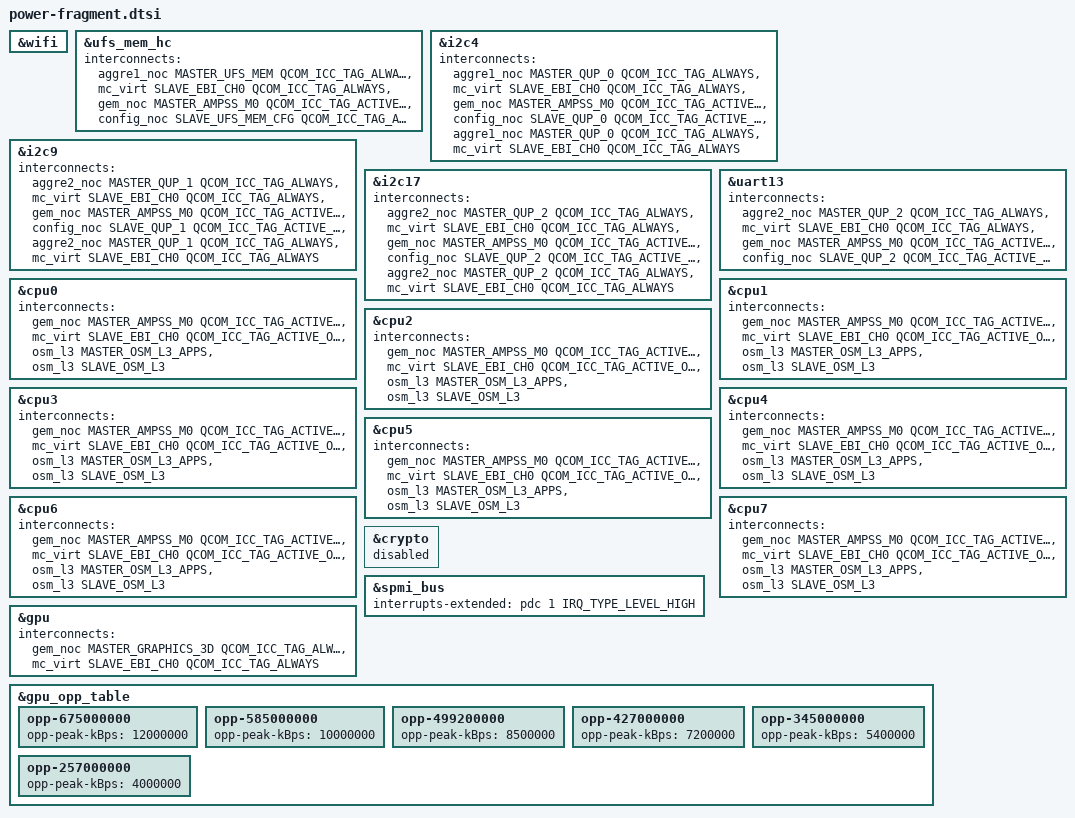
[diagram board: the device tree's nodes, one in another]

/* Idle power test (2026-11-10): ath10k holds both clocks for as long as
 * Wi-Fi is up. rf_clk2 keeps CXO on (blocks aosd); qdss is a debug vote.
 * Both are optional in ath10k_snoc. Test whether WCN3990 still works with
 * the crystal requested by its own pin, as on Android. */
&wifi {
	/delete-property/ clocks;
	/delete-property/ clock-names;
};

/* Interconnect votes missing from sm8150.dtsi (2026-11-10). qnoc-sm8150 had
 * no sync_state, so every NoC/DDR stayed at boot bandwidth (INT_MAX) forever
 * and the SoC could never sleep. With sync_state added, masters without
 * votes lose their bus: UFS (aggre1 path) and the QUP core clock (bcm_qup0,
 * which only QUP master paths vote) stall and the phone crashes. Give them
 * votes as sm8250 does. The device->DDR paths must be tagged "always":
 * tagged active-only they vanish from the bus the moment the last CPU
 * idles, even with a transfer in flight, and UFS then stalls for good
 * (seen 2026-11-12: every block tag stuck, phone half dead). The drivers
 * drop these votes themselves when the device is idle (UFS clock gating,
 * GENI runtime suspend). Only the cpu->register paths are active-only.
 * The QUP core clock
 * BCM sits on the QUP master nodes (no qup_virt on sm8150), so a QUP->DDR
 * path doubles as "qup-core". */
#include <dt-bindings/interconnect/qcom,icc.h>

&ufs_mem_hc {
	interconnects = <&aggre1_noc MASTER_UFS_MEM QCOM_ICC_TAG_ALWAYS &mc_virt SLAVE_EBI_CH0 QCOM_ICC_TAG_ALWAYS>,
			<&gem_noc MASTER_AMPSS_M0 QCOM_ICC_TAG_ACTIVE_ONLY &config_noc SLAVE_UFS_MEM_CFG QCOM_ICC_TAG_ACTIVE_ONLY>;
	interconnect-names = "ufs-ddr", "cpu-ufs";
};

&i2c4 {
	interconnects = <&aggre1_noc MASTER_QUP_0 QCOM_ICC_TAG_ALWAYS &mc_virt SLAVE_EBI_CH0 QCOM_ICC_TAG_ALWAYS>,
			<&gem_noc MASTER_AMPSS_M0 QCOM_ICC_TAG_ACTIVE_ONLY &config_noc SLAVE_QUP_0 QCOM_ICC_TAG_ACTIVE_ONLY>,
			<&aggre1_noc MASTER_QUP_0 QCOM_ICC_TAG_ALWAYS &mc_virt SLAVE_EBI_CH0 QCOM_ICC_TAG_ALWAYS>;
	interconnect-names = "qup-core", "qup-config", "qup-memory";
};

&i2c9 {
	interconnects = <&aggre2_noc MASTER_QUP_1 QCOM_ICC_TAG_ALWAYS &mc_virt SLAVE_EBI_CH0 QCOM_ICC_TAG_ALWAYS>,
			<&gem_noc MASTER_AMPSS_M0 QCOM_ICC_TAG_ACTIVE_ONLY &config_noc SLAVE_QUP_1 QCOM_ICC_TAG_ACTIVE_ONLY>,
			<&aggre2_noc MASTER_QUP_1 QCOM_ICC_TAG_ALWAYS &mc_virt SLAVE_EBI_CH0 QCOM_ICC_TAG_ALWAYS>;
	interconnect-names = "qup-core", "qup-config", "qup-memory";
};

&i2c17 {
	interconnects = <&aggre2_noc MASTER_QUP_2 QCOM_ICC_TAG_ALWAYS &mc_virt SLAVE_EBI_CH0 QCOM_ICC_TAG_ALWAYS>,
			<&gem_noc MASTER_AMPSS_M0 QCOM_ICC_TAG_ACTIVE_ONLY &config_noc SLAVE_QUP_2 QCOM_ICC_TAG_ACTIVE_ONLY>,
			<&aggre2_noc MASTER_QUP_2 QCOM_ICC_TAG_ALWAYS &mc_virt SLAVE_EBI_CH0 QCOM_ICC_TAG_ALWAYS>;
	interconnect-names = "qup-core", "qup-config", "qup-memory";
};

&uart13 {
	interconnects = <&aggre2_noc MASTER_QUP_2 QCOM_ICC_TAG_ALWAYS &mc_virt SLAVE_EBI_CH0 QCOM_ICC_TAG_ALWAYS>,
			<&gem_noc MASTER_AMPSS_M0 QCOM_ICC_TAG_ACTIVE_ONLY &config_noc SLAVE_QUP_2 QCOM_ICC_TAG_ACTIVE_ONLY>;
	interconnect-names = "qup-core", "qup-config";
};

/* cpu DDR vote (2026-11-12). Tag 0 means "always": the
 * cpufreq DDR bandwidth vote stayed in the RPMh sleep set, so DDR and the NoCs were never released
 * while every CPU was power-collapsed (aosd/cxsd/ddr stuck at 0). Vendor
 * kernels vote these in the active set only. */
&cpu0 {
	interconnects = <&gem_noc MASTER_AMPSS_M0 QCOM_ICC_TAG_ACTIVE_ONLY &mc_virt SLAVE_EBI_CH0 QCOM_ICC_TAG_ACTIVE_ONLY>,
			<&osm_l3 MASTER_OSM_L3_APPS &osm_l3 SLAVE_OSM_L3>;
};

&cpu1 {
	interconnects = <&gem_noc MASTER_AMPSS_M0 QCOM_ICC_TAG_ACTIVE_ONLY &mc_virt SLAVE_EBI_CH0 QCOM_ICC_TAG_ACTIVE_ONLY>,
			<&osm_l3 MASTER_OSM_L3_APPS &osm_l3 SLAVE_OSM_L3>;
};

&cpu2 {
	interconnects = <&gem_noc MASTER_AMPSS_M0 QCOM_ICC_TAG_ACTIVE_ONLY &mc_virt SLAVE_EBI_CH0 QCOM_ICC_TAG_ACTIVE_ONLY>,
			<&osm_l3 MASTER_OSM_L3_APPS &osm_l3 SLAVE_OSM_L3>;
};

&cpu3 {
	interconnects = <&gem_noc MASTER_AMPSS_M0 QCOM_ICC_TAG_ACTIVE_ONLY &mc_virt SLAVE_EBI_CH0 QCOM_ICC_TAG_ACTIVE_ONLY>,
			<&osm_l3 MASTER_OSM_L3_APPS &osm_l3 SLAVE_OSM_L3>;
};

&cpu4 {
	interconnects = <&gem_noc MASTER_AMPSS_M0 QCOM_ICC_TAG_ACTIVE_ONLY &mc_virt SLAVE_EBI_CH0 QCOM_ICC_TAG_ACTIVE_ONLY>,
			<&osm_l3 MASTER_OSM_L3_APPS &osm_l3 SLAVE_OSM_L3>;
};

&cpu5 {
	interconnects = <&gem_noc MASTER_AMPSS_M0 QCOM_ICC_TAG_ACTIVE_ONLY &mc_virt SLAVE_EBI_CH0 QCOM_ICC_TAG_ACTIVE_ONLY>,
			<&osm_l3 MASTER_OSM_L3_APPS &osm_l3 SLAVE_OSM_L3>;
};

&cpu6 {
	interconnects = <&gem_noc MASTER_AMPSS_M0 QCOM_ICC_TAG_ACTIVE_ONLY &mc_virt SLAVE_EBI_CH0 QCOM_ICC_TAG_ACTIVE_ONLY>,
			<&osm_l3 MASTER_OSM_L3_APPS &osm_l3 SLAVE_OSM_L3>;
};

&cpu7 {
	interconnects = <&gem_noc MASTER_AMPSS_M0 QCOM_ICC_TAG_ACTIVE_ONLY &mc_virt SLAVE_EBI_CH0 QCOM_ICC_TAG_ACTIVE_ONLY>,
			<&osm_l3 MASTER_OSM_L3_APPS &osm_l3 SLAVE_OSM_L3>;
};

/* The crypto engine holds a fixed DDR vote for as long as its driver is
 * bound and nothing uses it (ARMv8 CE is faster). Off. */
&crypto {
	status = "disabled";
};

/* PMIC wake through the PDC (2026-11-14). sm8150.dtsi wires the SPMI arbiter
 * interrupt straight to the GIC (SPI 481). In XO shutdown / AOSS sleep the GIC
 * is off and only PDC-routed interrupts wake the SoC, so the RTC alarm, the
 * charger and USB plug events could never wake it: the first real deep sleep
 * looked like a hang (no watchdog, no answer until a forced reset). sm8250
 * routes it as PDC pin 1, which maps to SPI 481 (qcom,pdc-ranges <0 480 94>). */
&spmi_bus {
	/delete-property/ interrupts;
	interrupts-extended = <&pdc 1 IRQ_TYPE_LEVEL_HIGH>;
};

/* GPU DDR bandwidth (2026-11-14). The A640 GMU table in a6xx_hfi.c is a
 * single "off" level (no bus scaling), and sm8150.dtsi gives the GPU no
 * interconnect path, so the GPU only had memory bandwidth from the boot
 * vote. With interconnect sync_state the boot vote goes away and glmark2
 * dropped from 534 to 238. a6xx calls dev_pm_opp_set_opp() on every
 * frequency change (and with NULL when the GPU suspends), so a gfx-mem path
 * plus opp-peak-kBps votes DDR per GPU level, as sc7180/sc7280 do. */
&gpu {
	interconnects = <&gem_noc MASTER_GRAPHICS_3D QCOM_ICC_TAG_ALWAYS
			 &mc_virt SLAVE_EBI_CH0 QCOM_ICC_TAG_ALWAYS>;
	interconnect-names = "gfx-mem";
};

&gpu_opp_table {
	opp-675000000 { opp-peak-kBps = <12000000>; };
	opp-585000000 { opp-peak-kBps = <10000000>; };
	opp-499200000 { opp-peak-kBps = <8500000>; };
	opp-427000000 { opp-peak-kBps = <7200000>; };
	opp-345000000 { opp-peak-kBps = <5400000>; };
	opp-257000000 { opp-peak-kBps = <4000000>; };
};
